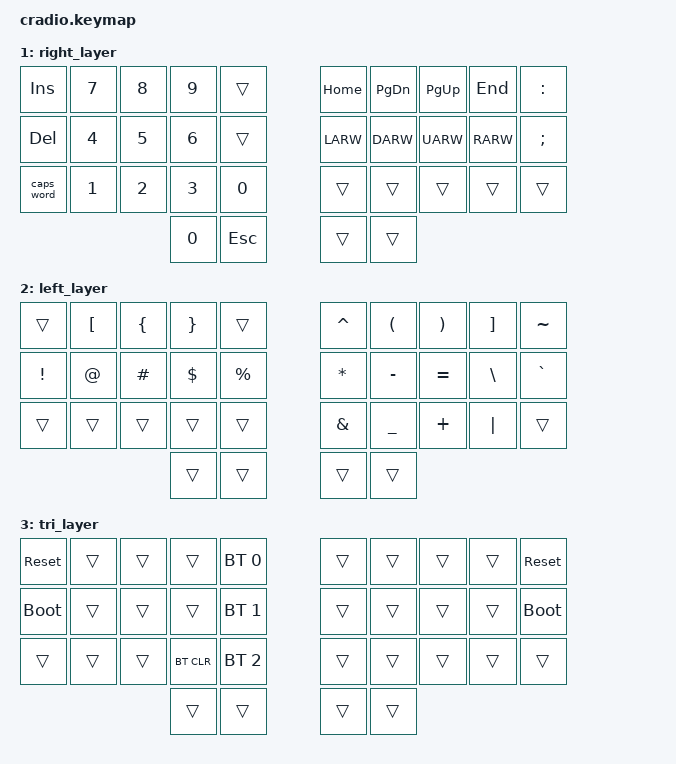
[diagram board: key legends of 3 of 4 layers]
// Copyright (c) 2022 The ZMK Contributors
// SPDX-License-Identifier: MIT

#include <behaviors.dtsi>
#include <dt-bindings/zmk/keys.h>
#include <dt-bindings/zmk/bt.h>

// Home row mods macro
#define HRML(k1,k2,k3,k4) &ht LCTRL k1  &ht LALT k2  &ht LGUI  k3  &ht LSHFT k4
#define HRMR(k1,k2,k3,k4) &ht LSHFT k1  &ht LGUI k2  &ht LALT  k3  &ht LCTRL k4

/ {
    combos {
        compatible = "zmk,combos";
        combo_esc {
            timeout-ms = <50>;
            key-positions = <0 1>;
            bindings = <&kp ESC>;
        };
    };
};

/ {
    behaviors {
        ht: hold_tap {
            label = "hold_tap";
            compatible = "zmk,behavior-hold-tap";
            #binding-cells = <2>;
            flavor = "tap-preferred";
            tapping-term-ms = <220>;
            quick-tap-ms = <150>;
            global-quick-tap;
            bindings = <&kp>, <&kp>;
        };
    };

    conditional_layers {
        compatible = "zmk,conditional-layers";
        tri_layer {
            if-layers = <1 2>;
            then-layer = <3>;
        };
    };

    keymap {
        compatible = "zmk,keymap";
        default_layer {
            bindings = <
        //╭──────────┬──────────┬──────────┬──────────┬──────────╮   ╭──────────┬──────────┬──────────┬──────────┬──────────╮
        //│  Q       │  W       │  F       │  P       │  B       │   │  J       │  L       │  U       │  Y       │  ' "     │
            &kp Q      &kp W      &kp F      &kp P      &kp B          &kp J      &kp L      &kp U      &kp Y      &kp SQT
        //├──────────┼──────────┼──────────┼──────────┼──────────┤   ├──────────┼──────────┼──────────┼──────────┼──────────┤
        //│  A       │  R       │  S       │  T       │  G       │   │  M       │  N       │  E       │   I      │  O       │
            HRML(A,        R,         S,         T)     &kp G          &kp M      HRMR(N,        E,         I,         O)
        //├──────────┼──────────┼──────────┼──────────┼──────────┤   ├──────────┼──────────┼──────────┼──────────┼──────────┤
        //│  Z       │  X       │  C       │  D       │  V       │   │  K       │  H       │ , <      │ . >      │ / ?      │
            &kp Z      &kp X      &kp C      &kp D      &kp V          &kp K      &kp H      &kp COMMA  &kp DOT    &kp FSLH
        //╰──────────┴──────────┴──────────┼──────────┼──────────┤   ├──────────┼──────────┼──────────┴──────────┴──────────╯
                                             &kp TAB   &lt 2 SPACE     &lt 1 BSPC  &kp ENTER
        //                                 ╰──────────┴──────────╯   ╰──────────┴──────────╯
            >;
        };

        right_layer {
            bindings = <
        //╭──────────┬──────────┬──────────┬──────────┬──────────╮   ╭──────────┬──────────┬──────────┬──────────┬──────────╮
        //│ INSERT   │  7       │  8       │  9       │          │   │ HOME     │ PAGE DN  │ PAGE UP  │ END      │  :       │
            &kp INS    &kp N7     &kp N8     &kp N9     &trans         &kp HOME   &kp PG_DN  &kp PG_UP  &kp END    &kp COLON
        //├──────────┼──────────┼──────────┼──────────┼──────────┤   ├──────────┼──────────┼──────────┼──────────┼──────────┤
        //│ DELETE   │  4       │  5       │  6       │          │   │ LEFT     │ DOWN     │ UP       │ RIGHT    │  ;       │
            &kp DEL    &kp N4     &kp N5     &kp N6     &trans         &kp LARW   &kp DARW   &kp UARW   &kp RARW   &kp SEMI
        //├──────────┼──────────┼──────────┼──────────┼──────────┤   ├──────────┼──────────┼──────────┼──────────┼──────────┤
        //│ CAPS     │  1       │  2       │  3       │  0       │   │          │          │          │          │          │
           &caps_word  &kp N1     &kp N2     &kp N3     &kp N0         &trans     &trans     &trans     &trans     &trans
        //╰──────────┴──────────┴──────────┼──────────┼──────────┤   ├──────────┼──────────┼──────────┴──────────┴──────────╯
                                             &kp N0     &kp ESC        &trans     &trans
        //                                 ╰──────────┴──────────╯   ╰──────────┴──────────╯
            >;
        };

        left_layer {
            bindings = <
        //╭──────────┬──────────┬──────────┬──────────┬──────────╮   ╭──────────┬──────────┬──────────┬──────────┬──────────╮
        //│          │  [       │  {       │  }       │          │   │  ^       │  (       │  )       │  ]       │  ~       │
            &trans     &kp LBKT   &kp LBRC   &kp RBRC   &trans         &kp CARET  &kp LPAR   &kp RPAR   &kp RBKT   &kp TILDE
        //├──────────┼──────────┼──────────┼──────────┼──────────┤   ├──────────┼──────────┼──────────┼──────────┼──────────┤
        //│  !       │  @       │  #       │  $       │  %       │   │  *       │  -       │  =       │  \       │  `       │
            &kp EXCL   &kp AT     &kp HASH   &kp DLLR   &kp PRCNT      &kp ASTRK  &kp MINUS  &kp EQUAL  &kp BSLH   &kp GRAVE
        //├──────────┼──────────┼──────────┼──────────┼──────────┤   ├──────────┼──────────┼──────────┼──────────┼──────────┤
        //│          │          │          │          │          │   │  &       │  _       │  +       │  │       │          │
            &trans     &trans     &trans     &trans     &trans         &kp AMPS   &kp UNDER  &kp PLUS   &kp PIPE   &trans
        //╰──────────┴──────────┴──────────┼──────────┼──────────┤   ├──────────┼──────────┼──────────┴──────────┴──────────╯
                                             &trans     &trans         &trans     &trans
        //                                 ╰──────────┴──────────╯   ╰──────────┴──────────╯
            >;
        };

        tri_layer {
            bindings = <
        //╭──────────┬──────────┬──────────┬──────────┬──────────╮   ╭──────────┬──────────┬──────────┬──────────┬──────────╮
        //│ RESET    │          │          │          │PROFILE 0 │   │          │          │          │          │  RESET   │
           &sys_reset  &trans     &trans     &trans    &bt BT_SEL 0    &trans     &trans     &trans     &trans    &sys_reset
        //├──────────┼──────────┼──────────┼──────────┼──────────┤   ├──────────┼──────────┼──────────┼──────────┼──────────┤
        //│BOOTLOADER│          │          │          │PROFILE 1 │   │          │          │          │          │BOOTLOADER│
          &bootloader  &trans     &trans     &trans    &bt BT_SEL 1    &trans     &trans     &trans     &trans    &bootloader
        //├──────────┼──────────┼──────────┼──────────┼──────────┤   ├──────────┼──────────┼──────────┼──────────┼──────────┤
        //│          │          │          │ CLEAR BT │PROFILE 2 │   │          │          │          │          │          │
            &trans     &trans     &trans    &bt BT_CLR &bt BT_SEL 2    &trans     &trans     &trans     &trans     &trans
        //╰──────────┴──────────┴──────────┼──────────┼──────────┤   ├──────────┼──────────┼──────────┴──────────┴──────────╯
                                             &trans     &trans         &trans     &trans
        //                                 ╰──────────┴──────────╯   ╰──────────┴──────────╯
            >;
        };
    };
};
